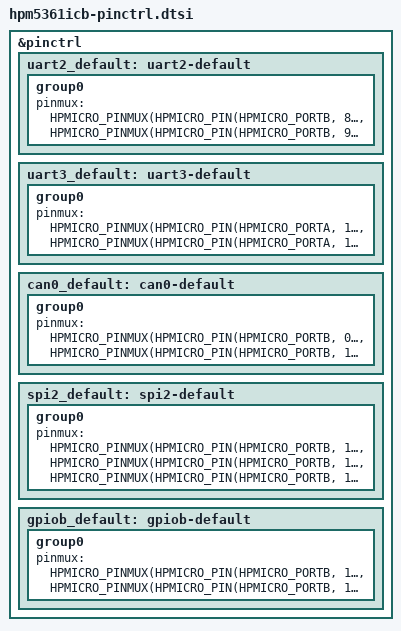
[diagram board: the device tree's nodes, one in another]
/*
 * Copyright (c) 2026 HPMicro
 * SPDX-License-Identifier: Apache-2.0
 */

#include "dt-bindings/pinctrl/hpmicro-pinctrl-common.h"

&pinctrl {
	uart2_default: uart2-default {
		group0 {
			pinmux = <HPMICRO_PINMUX(HPMICRO_PIN(HPMICRO_PORTB, 8), IOC_TYPE_IOC, 0, 2)>,
					 <HPMICRO_PINMUX(HPMICRO_PIN(HPMICRO_PORTB, 9), IOC_TYPE_IOC, 0, 2)>;
		};
	};

	uart3_default: uart3-default {
		group0 {
			pinmux = <HPMICRO_PINMUX(HPMICRO_PIN(HPMICRO_PORTA, 15), IOC_TYPE_IOC, 0, 2)>,
					 <HPMICRO_PINMUX(HPMICRO_PIN(HPMICRO_PORTA, 14), IOC_TYPE_IOC, 0, 2)>;
		};
	};

	can0_default: can0-default {
		group0 {
			pinmux = <HPMICRO_PINMUX(HPMICRO_PIN(HPMICRO_PORTB, 0), IOC_TYPE_IOC, 0, 7)>,
					 <HPMICRO_PINMUX(HPMICRO_PIN(HPMICRO_PORTB, 1), IOC_TYPE_IOC, 0, 7)>;
		};
	};

	spi2_default: spi2-default {
		group0 {
			pinmux = <HPMICRO_PINMUX(HPMICRO_PIN(HPMICRO_PORTB, 11), IOC_TYPE_IOC, 0, 5)>,
					 <HPMICRO_PINMUX(HPMICRO_PIN(HPMICRO_PORTB, 12), IOC_TYPE_IOC, 0, 5)>,
					 <HPMICRO_PINMUX(HPMICRO_PIN(HPMICRO_PORTB, 13), IOC_TYPE_IOC, 0, 5)>;
		};
	};

	gpiob_default: gpiob-default {
		group0 {
			pinmux = <HPMICRO_PINMUX(HPMICRO_PIN(HPMICRO_PORTB, 10), IOC_TYPE_IOC, 0, 0)>,
					 <HPMICRO_PINMUX(HPMICRO_PIN(HPMICRO_PORTB, 15), IOC_TYPE_IOC, 0, 0)>;
		};
	};
};
